# nrf52811 register map
Vendor: Nordic Semiconductor; Series: nrf52; File version: 1
CPU: CM4 r0p1, little endian, MPU, no FPU, 3 interrupt priority bits
Registers are 32-bit, read-write, reset 0x0 unless marked. A register's access mark holds for its fields unless they carry their own. Offsets are from the block's base; [hi:lo] are bit positions; lines under a group give offsets from that group; {n}, {i} and the like mark numbered series; 'fields as' and 'values as' point back to an identical list.

## POWER — Power control
Base 0x40000000; alternate view of APPROTECT
0x78 TASKS_CONSTLAT wo — Enable Constant Latency mode
  [0] TASKS_CONSTLAT
    1=Trigger task
0x7C TASKS_LOWPWR wo — Enable Low-power mode (variable latency)
  [0] TASKS_LOWPWR
    1=Trigger task
0x108 EVENTS_POFWARN — Power failure warning
  [0] EVENTS_POFWARN
    0=NotGenerated (Event not generated); 1=Generated (Event generated)
0x114 EVENTS_SLEEPENTER — CPU entered WFI/WFE sleep
  [0] EVENTS_SLEEPENTER
    values as EVENTS_POFWARN.EVENTS_POFWARN
0x118 EVENTS_SLEEPEXIT — CPU exited WFI/WFE sleep
  [0] EVENTS_SLEEPEXIT
    values as EVENTS_POFWARN.EVENTS_POFWARN
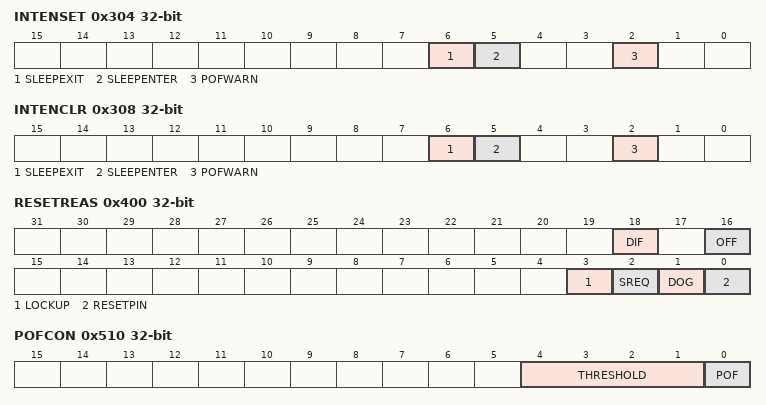
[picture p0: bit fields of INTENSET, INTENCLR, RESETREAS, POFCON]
0x304 INTENSET — Enable interrupt
  [all] fields
    on read: 0=Disabled (Read: Disabled); 1=Enabled (Read: Enabled) | on write: 1=Set (Enable)
  [6] SLEEPEXIT — Write '1' to enable interrupt for event SLEEPEXIT
  [5] SLEEPENTER — Write '1' to enable interrupt for event SLEEPENTER
  [2] POFWARN — Write '1' to enable interrupt for event POFWARN
0x308 INTENCLR — Disable interrupt
  [all] fields
    on read: 0=Disabled (Read: Disabled); 1=Enabled (Read: Enabled) | on write: 1=Clear (Disable)
  [6] SLEEPEXIT — Write '1' to disable interrupt for event SLEEPEXIT
  [5] SLEEPENTER — Write '1' to disable interrupt for event SLEEPENTER
  [2] POFWARN — Write '1' to disable interrupt for event POFWARN
0x400 RESETREAS — Reset reason
  [all] fields
    0=NotDetected; 1=Detected
  [18] DIF — Reset due to wake up from System OFF mode when wakeup is triggered from entering into debug interface mode
  [16] OFF — Reset due to wake up from System OFF mode when wakeup is triggered from DETECT signal from GPIO
  [3] LOCKUP — Reset from CPU lock-up detected
  [2] SREQ — Reset from soft reset detected
  [1] DOG — Reset from watchdog detected
  [0] RESETPIN — Reset from pin-reset detected
0x500 SYSTEMOFF wo
  [0] SYSTEMOFF — Enable System OFF mode
    1=Enter (Enable System OFF mode)
0x510 POFCON — Power failure comparator configuration
  [4:1] THRESHOLD — Power failure comparator threshold setting
    4=V17 (Set threshold to 1.7 V); 5=V18 (Set threshold to 1.8 V); 6=V19 (Set threshold to 1.9 V); 7=V20 (Set threshold to 2.0 V); 8=V21 (Set threshold to 2.1 V); 9=V22 (Set threshold to 2.2 V); 10=V23 (Set threshold to 2.3 V); 11=V24 (Set threshold to 2.4 V); 12=V25 (Set threshold to 2.5 V); 13=V26 (Set threshold to 2.6 V); 14=V27 (Set threshold to 2.7 V); 15=V28 (Set threshold to 2.8 V)
  [0] POF — Enable or disable power failure comparator
    0=Disabled; 1=Enabled
0x51C GPREGRET — General purpose retention register
  [7:0] GPREGRET
0x520 GPREGRET2 — General purpose retention register
  [7:0] GPREGRET
0x578 DCDCEN — DC/DC enable register
  [0] DCDCEN — Enable or disable DC/DC converter
    0=Disabled; 1=Enabled
{0x900+0x10*i} RAM[{i}] (i=0..7) group — Unspecified
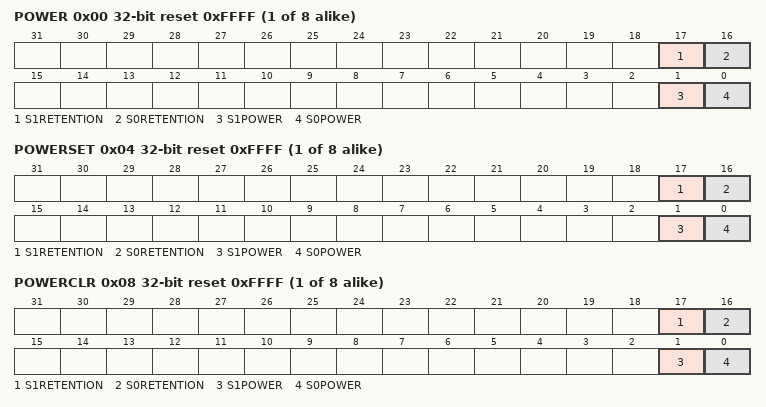
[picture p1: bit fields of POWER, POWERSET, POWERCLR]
  0x00 POWER reset 0xFFFF — Description cluster: RAMn power control register. The RAM size will vary depending on product variant, and the RAMn register will only be present if the corresponding RAM AHB slave is present on the device.
    [all] fields
      0=Off; 1=On
    [17] S1RETENTION — Keep retention on RAM section S1 when RAM section is in OFF
    [16] S0RETENTION — Keep retention on RAM section S0 when RAM section is in OFF
    [1] S1POWER — Keep RAM section S1 ON or OFF in System ON mode.
    [0] S0POWER — Keep RAM section S0 ON or OFF in System ON mode.
  0x04 POWERSET wo reset 0xFFFF — Description cluster: RAMn power control set register
    [all] fields
      1=On
    [17] S1RETENTION — Keep retention on RAM section S1 when RAM section is switched off
    [16] S0RETENTION — Keep retention on RAM section S0 when RAM section is switched off
    [1] S1POWER — Keep RAM section S1 of RAMn on or off in System ON mode
    [0] S0POWER — Keep RAM section S0 of RAMn on or off in System ON mode
  0x08 POWERCLR wo reset 0xFFFF — Description cluster: RAMn power control clear register
    [all] fields
      1=Off
    [17] S1RETENTION — Keep retention on RAM section S1 when RAM section is switched off
    [16] S0RETENTION — Keep retention on RAM section S0 when RAM section is switched off
    [1] S1POWER — Keep RAM section S1 of RAMn on or off in System ON mode
    [0] S0POWER — Keep RAM section S0 of RAMn on or off in System ON mode

## Notices in the file
Copyright (c) 2010 - 2025, Nordic Semiconductor ASA All rights reserved.
SPDX-License-Identifier: BSD-3-Clause
Redistribution and use in source and binary forms, with or without
modification, are permitted provided that the following conditions are met:
1. Redistributions of source code must retain the above copyright notice, this
list of conditions and the following disclaimer.
2. Redistributions in binary form must reproduce the above copyright
notice, this list of conditions and the following disclaimer in the
documentation and/or other materials provided with the distribution.
3. Neither the name of Nordic Semiconductor ASA nor the names of its
contributors may be used to endorse or promote products derived from this
software without specific prior written permission.
THIS SOFTWARE IS PROVIDED BY THE COPYRIGHT HOLDERS AND CONTRIBUTORS "AS IS"
AND ANY EXPRESS OR IMPLIED WARRANTIES, INCLUDING, BUT NOT LIMITED TO, THE
IMPLIED WARRANTIES OF MERCHANTABILITY, AND FITNESS FOR A PARTICULAR PURPOSE
ARE DISCLAIMED. IN NO EVENT SHALL NORDIC SEMICONDUCTOR ASA OR CONTRIBUTORS BE
LIABLE FOR ANY DIRECT, INDIRECT, INCIDENTAL, SPECIAL, EXEMPLARY, OR
CONSEQUENTIAL DAMAGES (INCLUDING, BUT NOT LIMITED TO, PROCUREMENT OF
SUBSTITUTE GOODS OR SERVICES; LOSS OF USE, DATA, OR PROFITS; OR BUSINESS
INTERRUPTION) HOWEVER CAUSED AND ON ANY THEORY OF LIABILITY, WHETHER IN
CONTRACT, STRICT LIABILITY, OR TORT (INCLUDING NEGLIGENCE OR OTHERWISE)
ARISING IN ANY WAY OUT OF THE USE OF THIS SOFTWARE, EVEN IF ADVISED OF THE
POSSIBILITY OF SUCH DAMAGE.
